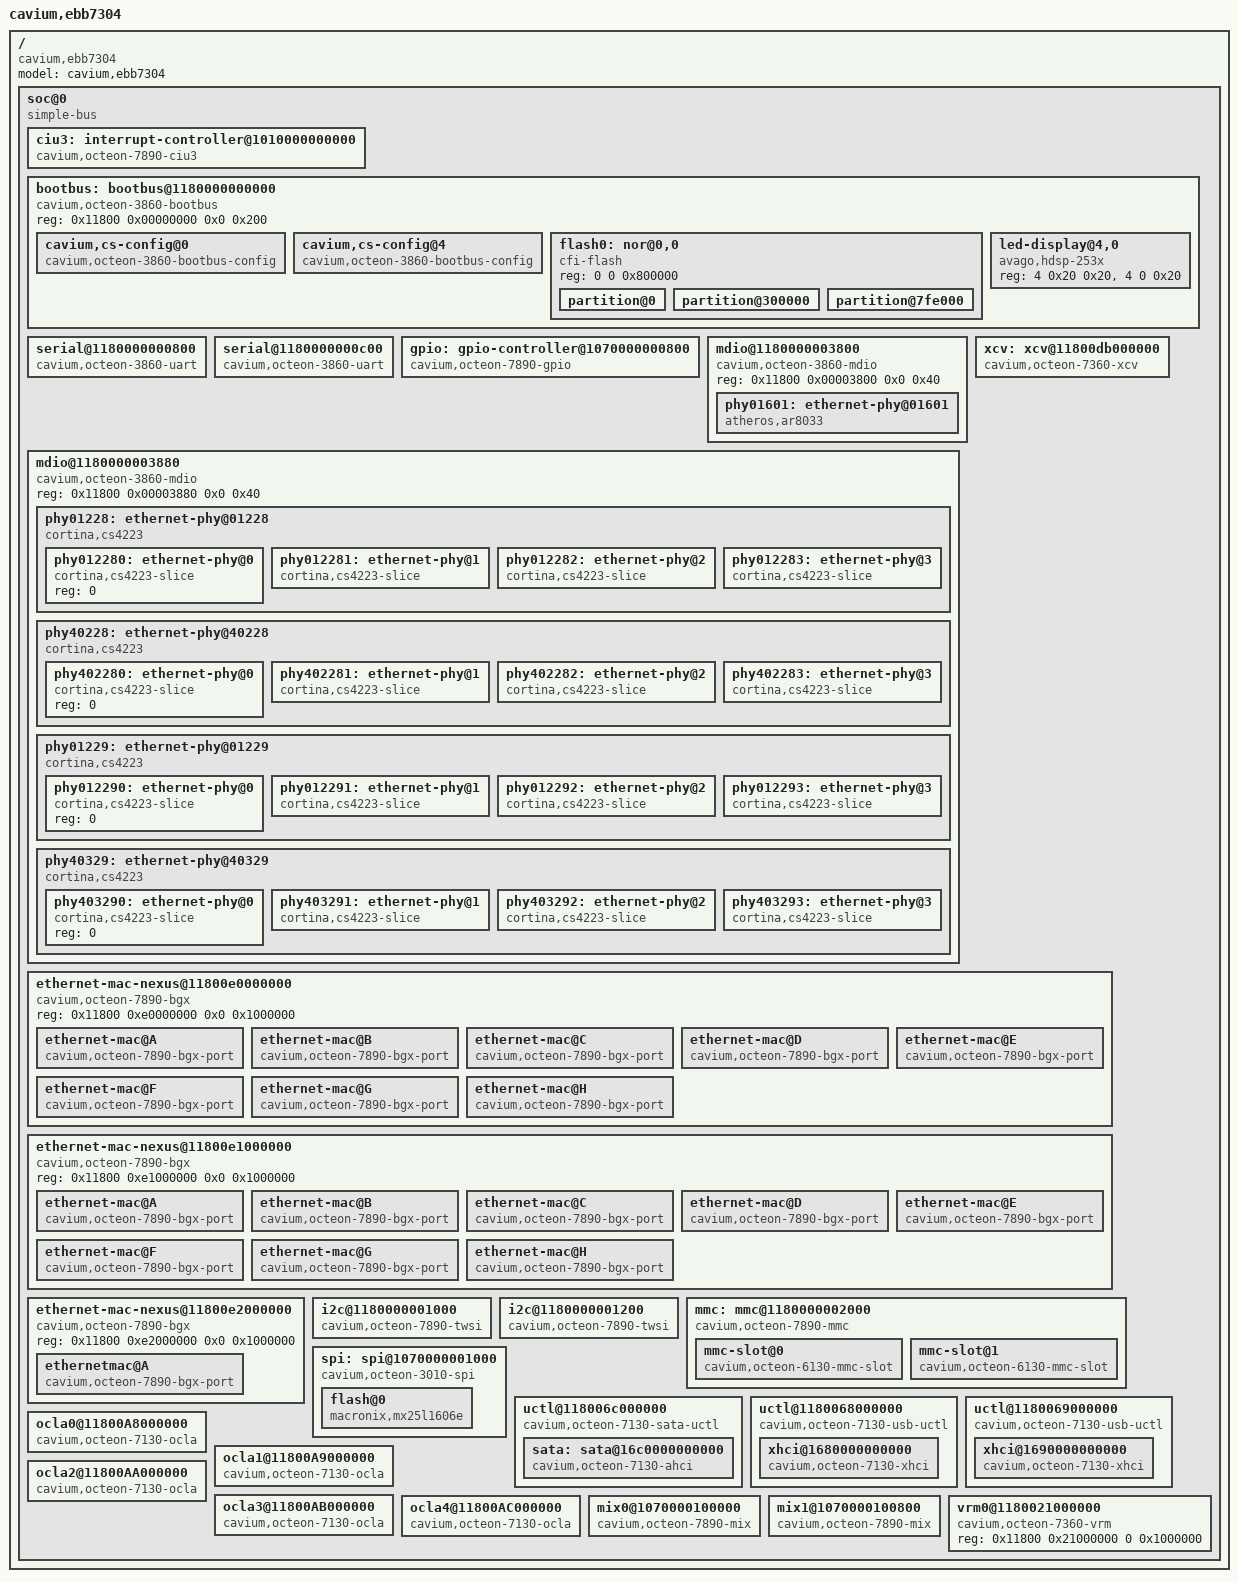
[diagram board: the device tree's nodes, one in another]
/dts-v1/;
/*
 * UBNT E1000
 */
/ {
	model = "cavium,ebb7304";
	compatible = "cavium,ebb7304";
	#address-cells = <2>;
	#size-cells = <2>;

	soc@0 {
		interrupt-parent = <&ciu3>;
		compatible = "simple-bus";
		#address-cells = <2>;
		#size-cells = <2>;
		ranges; /* Direct mapping */
		cavium,node-trim = "0,soc";

		ciu3: interrupt-controller@1010000000000 {
			compatible = "cavium,octeon-7890-ciu3";
			interrupt-controller;
			/* Interrupts are specified by two parts:
			 * 1) Source number (20 significant bits)
			 * 2) Trigger type: (4 == level, 1 == edge)
			 */
			#address-cells = <0>;
			#interrupt-cells = <2>;
			reg = <0x10100 0x00000000 0x0 0xb0000000>;
		};

		bootbus: bootbus@1180000000000 {
			compatible = "cavium,octeon-3860-bootbus";
			reg = <0x11800 0x00000000 0x0 0x200>;
			/* The chip select number and offset */
			#address-cells = <2>;
			/* The size of the chip select region */
			#size-cells = <1>;
			ranges = <0 0  0       0x1f400000  0xc00000>,
				 <1 0  0x10000 0x10000000  0>,
				 <2 0  0x10000 0x20000000  0>,
				 <3 0  0x10000 0x30000000  0>,
				 <4 0  0       0x1d020000  0x10000>,
				 <5 0  0x10000 0x50000000  0>,
				 <6 0  0x10000 0x60000000  0>,
				 <7 0  0x10000 0x70000000  0>;

			cavium,cs-config@0 {
				compatible = "cavium,octeon-3860-bootbus-config";
				cavium,cs-index = <0>;
				cavium,t-adr  = <10>;
				cavium,t-ce   = <50>;
				cavium,t-oe   = <50>;
				cavium,t-we   = <35>;
				cavium,t-rd-hld = <25>;
				cavium,t-wr-hld = <35>;
				cavium,t-pause  = <0>;
				cavium,t-wait   = <50>;
				cavium,t-page   = <30>;
				cavium,t-rd-dly = <0>;

				cavium,page-mode = <1>;
				cavium,pages     = <8>;
				cavium,bus-width = <8>;
			};
			cavium,cs-config@4 {
				compatible = "cavium,octeon-3860-bootbus-config";
				cavium,cs-index = <4>;
				cavium,t-adr  = <10>;
				cavium,t-ce   = <10>;
				cavium,t-oe   = <160>;
				cavium,t-we   = <100>;
				cavium,t-rd-hld = <10>;
				cavium,t-wr-hld = <0>;
				cavium,t-pause  = <50>;
				cavium,t-wait   = <50>;
				cavium,t-page   = <10>;
				cavium,t-rd-dly = <10>;

				cavium,pages     = <0>;
				cavium,bus-width = <8>;
			};
			flash0: nor@0,0 {
				compatible = "cfi-flash";
				reg = <0 0 0x800000>;
				#address-cells = <1>;
				#size-cells = <1>;

				partition@0 {
					label = "bootloader";
					reg = <0 0x340000>;
					read-only;
				};
				partition@300000 {
					label = "storage";
					reg = <0x340000 0x4be000>;
				};
				partition@7fe000 {
					label = "environment";
					reg = <0x7fe000 0x2000>;
					read-only;
				};
			};
			led-display@4,0 {
				compatible = "avago,hdsp-253x";
				reg = <4 0x20 0x20>, <4 0 0x20>;
			};
		};

		serial@1180000000800 {
			compatible = "cavium,octeon-3860-uart","ns16550";
			reg = <0x11800 0x00000800 0x0 0x400>;
			clock-frequency = <0>;
			current-speed = <115200>;
			reg-shift = <3>;
			interrupts = <0x08000 4>;
		};

		serial@1180000000c00 {
			compatible = "cavium,octeon-3860-uart","ns16550";
			reg = <0x11800 0x00000c00 0x0 0x400>;
			clock-frequency = <0>;
			current-speed = <115200>;
			reg-shift = <3>;
			interrupts = <0x08040 4>;
		};

		gpio: gpio-controller@1070000000800 {
			#gpio-cells = <2>;
			compatible = "cavium,octeon-7890-gpio";
			reg = <0x10700 0x00000800 0x0 0x100>;
			gpio-controller;
			/* Interrupts are specified by two parts:
			 * 1) GPIO pin number (0..15)
			 * 2) Triggering (1 - edge rising
			 *		  2 - edge falling
			 *		  4 - level active high
			 *		  8 - level active low)
			 */
			interrupt-controller;
			#interrupt-cells = <2>;
			/* The GPIO pins connect to 16 consecutive CUI bits */
			interrupts = <0x03000 4>, <0x03001 4>,
				     <0x03002 4>, <0x03003 4>,
				     <0x03004 4>, <0x03005 4>,
				     <0x03006 4>, <0x03007 4>,
				     <0x03008 4>, <0x03009 4>,
				     <0x0300a 4>, <0x0300b 4>,
				     <0x0300c 4>, <0x0300d 4>,
				     <0x0300e 4>, <0x0300f 4>;
		};

		mdio@1180000003800 {
			compatible = "cavium,octeon-3860-mdio";
			#address-cells = <1>;
			#size-cells = <0>;
			reg = <0x11800 0x00003800 0x0 0x40>;
			
			phy01601: ethernet-phy@01601 {
				cavium,qlm-trim = "6,sgmii";
				reg = <0x1>;
				compatible = "atheros,ar8033", "ethernet-phy-ieee802.3-c22";
			};
		};
		
		/* SMI_1 -- Available on rev 2 and later boards */
		mdio@1180000003880 {
			compatible = "cavium,octeon-3860-mdio";
			#address-cells = <1>;
			#size-cells = <0>;
			reg = <0x11800 0x00003880 0x0 0x40>;

			/**
			 * The phy names are broken down as follows:
			 * (m)phyxxyzzs
			 * where:
			 *	xx = 01 for SGMII, 10 for DXAUI, 20 for RXAUI
			 *	     and 40 for XFI/LXAUI
			 *	y = QLM/DLM number
			 *	zz = PHY address (decimal)
			 *	s = sub-phy number in the case of the Cortina
			 *	    PHY
			 * a mphy is a nexus phy that contains one or more
			 * sub-phys, for example the Cortina CS4223.
			 */

			/* QLM 2 */
			phy01228: ethernet-phy@01228 {
				compatible = "cortina,cs4223", "ethernet-phy-nexus";
				cavium,qlm-trim = "2,sgmii";						  
				reg = <0x1c>;
				#address-cells = <1>;
				#size-cells = <0>;

				phy012280: ethernet-phy@0 {
					compatible = "cortina,cs4223-slice";
					reg = <0>;					
				};
				phy012281: ethernet-phy@1 {
					compatible = "cortina,cs4223-slice";
					reg = <1>;
					cavium,qlm-trim = "2,sgmii";
				};
				phy012282: ethernet-phy@2 {
					compatible = "cortina,cs4223-slice";
					reg = <2>;
					cavium,qlm-trim = "2,sgmii";
				};
				phy012283: ethernet-phy@3 {
					compatible = "cortina,cs4223-slice";
					reg = <3>;
					cavium,qlm-trim = "2,sgmii";
				};

			};
			
			phy40228: ethernet-phy@40228 {
				compatible = "cortina,cs4223", "ethernet-phy-nexus";
				cavium,qlm-trim = "2,xfi", "2,xlaui", "2,10G_KR",
						  "2,40G_KR4" ;
				reg = <0x1c>;
				#address-cells = <1>;
				#size-cells = <0>;
				/*interrupt-parent = <&gpio>;*/
				/*interrupt = <13 8>;*/
				/* The Cortina CS4223 can be used either as
				 * XFI or XLAUI.  In XFI, four separate ports
				 * are supported even though it's only a single
				 * PHY device.
				 */
				phy402280: ethernet-phy@0 {
					compatible = "cortina,cs4223-slice";
					reg = <0>;					
				};
				phy402281: ethernet-phy@1 {
					compatible = "cortina,cs4223-slice";
					reg = <1>;
					cavium,qlm-trim = "2,xfi","2,10G_KR";
				};
				phy402282: ethernet-phy@2 {
					compatible = "cortina,cs4223-slice";
					reg = <2>;
					cavium,qlm-trim = "2,xfi","2,10G_KR";
				};
				phy402283: ethernet-phy@3 {
					compatible = "cortina,cs4223-slice";
					reg = <3>;
					cavium,qlm-trim = "2,xfi","2,10G_KR";
				};
			};

			/* QLM 3 */
			
			phy01229: ethernet-phy@01229 {
				compatible = "cortina,cs4223", "ethernet-phy-nexus";
				cavium,qlm-trim = "3,sgmii";						  
				reg = <0x1d>;
				#address-cells = <1>;
				#size-cells = <0>;

				phy012290: ethernet-phy@0 {
					compatible = "cortina,cs4223-slice";
					reg = <0>;					
				};
				phy012291: ethernet-phy@1 {
					compatible = "cortina,cs4223-slice";
					reg = <1>;
					cavium,qlm-trim = "3,sgmii";
				};
				phy012292: ethernet-phy@2 {
					compatible = "cortina,cs4223-slice";
					reg = <2>;
					cavium,qlm-trim = "3,sgmii";
				};
				phy012293: ethernet-phy@3 {
					compatible = "cortina,cs4223-slice";
					reg = <3>;
					cavium,qlm-trim = "3,sgmii";
				};

			};
			
			phy40329: ethernet-phy@40329 {
				compatible = "cortina,cs4223", "ethernet-phy-nexus";
				cavium,qlm-trim = "3,xfi","3,xlaui","3,10G_KR",
						  "3,40G_KR4" ;
				#address-cells = <1>;
				#size-cells = <0>;
				reg = <0x1d>;
				interrupt-parent = <&gpio>;
				interrupt = <13 8>;
				/* The Cortina CS4223 can be used either as
				 * XFI or XLAUI.  In XFI, four separate ports
				 * are supported even though it's only a single
				 * PHY device.
				 */
				phy403290: ethernet-phy@0 {
					compatible = "cortina,cs4223-slice";
					reg = <0>;					
				};
				phy403291: ethernet-phy@1 {
					compatible = "cortina,cs4223-slice";
					reg = <1>;
					cavium,qlm-trim = "3,xfi","3,10G_KR";
				};
				phy403292: ethernet-phy@2 {
					compatible = "cortina,cs4223-slice";
					reg = <2>;
					cavium,qlm-trim = "3,xfi","3,10G_KR";
				};
				phy403293: ethernet-phy@3 {
					compatible = "cortina,cs4223-slice";
					reg = <3>;
					cavium,qlm-trim = "3,xfi","3,10G_KR";
				};
			};

			/* DLM 5*/
			
			/* DLM 6 */
			
		};

		xcv: xcv@11800db000000 {
			compatible = "cavium,octeon-7360-xcv";
			reg = <0x11800 0xdb000000 0x0 0x1000000>;
			#address-cells = <1>;
			#size-cells = <0>;
			cavium,xcv-trim = "0,xcv", "1,xcv", "2,xcv";
		};

		/* BGX definitions here must match sim_board.c settings. */
		/* BGX 0*/
		ethernet-mac-nexus@11800e0000000 {
			compatible = "cavium,octeon-7890-bgx";
			reg = <0x11800 0xe0000000 0x0 0x1000000>;
			#address-cells = <1>;
			#size-cells = <0>;

			/* SerDes 0 (XLAUI/XFI) */
			ethernet-mac@A {
				compatible = "cavium,octeon-7890-bgx-port";
				reg = <0>;
				local-mac-address = [ 00 00 00 00 00 00 ];
				phy-handle = <&phy402280>;
				cavium,qlm-trim = "2,xlaui", "2,xfi","2,10G_KR","2,40G_KR4";	
				
				
			};
			
			/* SerDes 1 (XFI) */
			ethernet-mac@B {
				compatible = "cavium,octeon-7890-bgx-port";
				reg = <1>;
				local-mac-address = [ 00 00 00 00 00 00 ];
				phy-handle = <&phy402281>;
				cavium,qlm-trim = "2,xfi","2,10G_KR";
				
			};
			
			/* SerDes 2 (XFI) */
			ethernet-mac@C {
				compatible = "cavium,octeon-7890-bgx-port";
				reg = <2>;
				local-mac-address = [ 00 00 00 00 00 00 ];
				phy-handle = <&phy402282>;
				cavium,qlm-trim = "2,xfi","2,10G_KR";
				
			};
			/* SerDes 3 (XFI) */
			ethernet-mac@D {
				compatible = "cavium,octeon-7890-bgx-port";
				reg = <3>;
				local-mac-address = [ 00 00 00 00 00 00 ];
				phy-handle = <&phy402283>;
				cavium,qlm-trim = "2,xfi","2,10G_KR";
				
			};

			/* SerDes 0 (SGMII) */
			ethernet-mac@E {
				compatible = "cavium,octeon-7890-bgx-port";
				reg = <0>;
				local-mac-address = [ 00 00 00 00 00 00 ];
				phy-handle = <&phy012280>;
				cavium,qlm-trim = "2,sgmii";	
			};

			ethernet-mac@F {
				compatible = "cavium,octeon-7890-bgx-port";
				reg = <1>;
				local-mac-address = [ 00 00 00 00 00 00 ];
				phy-handle = <&phy012281>;
				cavium,qlm-trim = "2,sgmii";	
			};

			ethernet-mac@G {
				compatible = "cavium,octeon-7890-bgx-port";
				reg = <2>;
				local-mac-address = [ 00 00 00 00 00 00 ];
				phy-handle = <&phy012282>;
				cavium,qlm-trim = "2,sgmii";	
			};

			ethernet-mac@H {
				compatible = "cavium,octeon-7890-bgx-port";
				reg = <3>;
				local-mac-address = [ 00 00 00 00 00 00 ];
				phy-handle = <&phy012283>;
				cavium,qlm-trim = "2,sgmii";	
			};
			
		};
		/* BGX 1*/
		ethernet-mac-nexus@11800e1000000 {
			compatible = "cavium,octeon-7890-bgx";
			reg = <0x11800 0xe1000000 0x0 0x1000000>;
			#address-cells = <1>;
			#size-cells = <0>;

			
			/* SerDes 0 (XLAUI/XFI) */
			ethernet-mac@A {
				compatible = "cavium,octeon-7890-bgx-port";
				reg = <0>;
				local-mac-address = [ 00 00 00 00 00 00 ];
				phy-handle = <&phy403290>;
				cavium,qlm-trim = "3,xlaui","3,xfi","3,10G_KR","3,40G_KR4";				
				
			};
			
			/* SerDes 1 (XFI) */
			ethernet-mac@B {
				compatible = "cavium,octeon-7890-bgx-port";
				reg = <1>;
				local-mac-address = [ 00 00 00 00 00 00 ];
				phy-handle = <&phy403291>;
				cavium,qlm-trim = "3,xfi","3,10G_KR";
				
			};
			/* SerDes 2 (XFI) */
			ethernet-mac@C {
				compatible = "cavium,octeon-7890-bgx-port";
				reg = <2>;
				local-mac-address = [ 00 00 00 00 00 00 ];
				phy-handle = <&phy403292>;
				cavium,qlm-trim = "3,xfi","3,10G_KR";
				
			};

			/* SerDes 3 (XFI) */
			ethernet-mac@D {
				compatible = "cavium,octeon-7890-bgx-port";
				reg = <3>;
				local-mac-address = [ 00 00 00 00 00 00 ];
				phy-handle = <&phy403293>;
				cavium,qlm-trim = "3,xfi","3,10G_KR";
				
			};

			/* SerDes 0 (SGMII) */
			ethernet-mac@E {
				compatible = "cavium,octeon-7890-bgx-port";
				reg = <0>;
				local-mac-address = [ 00 00 00 00 00 00 ];
				phy-handle = <&phy012290>;
				cavium,qlm-trim = "3,sgmii";	
			};

			ethernet-mac@F {
				compatible = "cavium,octeon-7890-bgx-port";
				reg = <1>;
				local-mac-address = [ 00 00 00 00 00 00 ];
				phy-handle = <&phy012291>;
				cavium,qlm-trim = "3,sgmii";	
			};

			ethernet-mac@G {
				compatible = "cavium,octeon-7890-bgx-port";
				reg = <2>;
				local-mac-address = [ 00 00 00 00 00 00 ];
				phy-handle = <&phy012292>;
				cavium,qlm-trim = "3,sgmii";	
			};

			ethernet-mac@H {
				compatible = "cavium,octeon-7890-bgx-port";
				reg = <3>;
				local-mac-address = [ 00 00 00 00 00 00 ];
				phy-handle = <&phy012293>;
				cavium,qlm-trim = "3,sgmii";	
			};
		
		};

		/* BGX 2 */
		ethernet-mac-nexus@11800e2000000 {
			compatible = "cavium,octeon-7890-bgx";
			reg = <0x11800 0xe2000000 0x0 0x1000000>;
			#address-cells = <1>;
			#size-cells = <0>;
			
			/* SerDes 0, may differ from PCS Lane/LMAC */
			ethernetmac@A {
				compatible = "cavium,octeon-7890-bgx-port";
				reg = <2>;
				local-mac-address = [ 00 00 00 00 00 00 ];
				phy-handle = <&phy01601>;
				cavium,qlm-trim = "6,sgmii";				
			};
		};

		i2c@1180000001000 {
			#address-cells = <1>;
			#size-cells = <0>;
			compatible = "cavium,octeon-7890-twsi";
			cavium,cpu-trim = "0,notrev1.0";
			reg = <0x11800 0x00001000 0x0 0x200>;
			/* INT_ST, INT_TS, INT_CORE */
			interrupts = <0x0b000 1>, <0x0b001 1>, <0x0b002 1>;
			clock-frequency = <100000>;
		};

		i2c@1180000001200 {
			#address-cells = <1>;
			#size-cells = <0>;
			compatible = "cavium,octeon-7890-twsi";
			reg = <0x11800 0x00001200 0x0 0x200>;
			/* INT_ST, INT_TS, INT_CORE */
			interrupts = <0x0b100 1>, <0x0b101 1>, <0x0b102 1>;
			clock-frequency = <100000>;
		};

		mmc: mmc@1180000002000 {
			compatible = "cavium,octeon-7890-mmc",
				     "cavium,octeon-7360-mmc";
			reg = <0x11800 0x00002000 0x0 0x100>,
			      <0x11800 0x00000180 0x0 0x20>;
			#address-cells = <1>;
			#size-cells = <0>;
			/* EMM_INT_BUF_DONE,
			   EMM_INT_CMD_DONE,
			   EMM_INT_DMA_DONE,
			   EMM_INT_CMD_ERR,
			   EMM_INT_DMA_ERR,
			   EMM_INT_SWITCH_DONE,
			   EMM_INT_SWITCH_ERR,
			   EMM_DMA_DONE,
			   EMM_DMA_FIFO*/
			interrupts = <0x09040 1>,
				     <0x09041 1>,
				     <0x09042 1>,
				     <0x09043 1>,
				     <0x09044 1>,
				     <0x09045 1>,
				     <0x09046 1>,
				     <0x09000 1>,
				     <0x09001 1>;

			/* Power on GPIO 8, active high */
			power-gpios = <&gpio 8 0>;

			/* The board has two MMC slots
			 * If both are occupied, the speed must be reduced,
			 * as extra data-line load increases slew time,
			 * and dat-skew adjustment does not help significantly.
			 */
			mmc-slot@0 {
				compatible = "cavium,octeon-6130-mmc-slot";
				reg = <0>;
				voltage-ranges = <3300 3300>;
				//spi-max-frequency = <52000000>; // just one
				spi-max-frequency = <26000000>; // both slots
				/* bus width can be 1, 4 or 8 */
				bus-width = <8>; /* new std property */
				cavium,bus-max-width = <8>; /* custom property */
				
			};

			mmc-slot@1 {
				compatible = "cavium,octeon-6130-mmc-slot";
				reg = <1>;
				voltage-ranges = <3300 3300>;
				//spi-max-frequency = <52000000>; // just one
				spi-max-frequency = <26000000>; // both slots
				/* bus width can be 1, 4 or 8 */
				bus-width = <8>; /* new std property */
				cavium,bus-max-width = <8>; /* custom property */
				
			};
		};

		spi: spi@1070000001000 {
			compatible = "cavium,octeon-3010-spi";
			reg = <0x10700 0x00001000 0x0 0x100>;
			interrupts = <0x05001 1>;
			#address-cells = <1>;
			#size-cells = <0>;
			spi-max-frequency = <25000000>;

			flash@0 {
				compatible = "macronix,mx25l1606e","spi-flash";
				reg = <0>;
				spi-max-frequency = <75000000>;

				pagesize = <0x10000>;
				size = <0x1000000>;
				address-width = <32>;
			};
		};

		uctl@118006c000000 {
			compatible = "cavium,octeon-7130-sata-uctl";
			reg = <0x11800 0x6c000000 0x0 0x100>;
			ranges; /* Direct mapping */
			#address-cells = <2>;
			#size-cells = <2>;
			portmap = <0x3>;
			staggered-spinup;
			cavium,qlm-trim = "4,sata";

			sata: sata@16c0000000000 {
				compatible = "cavium,octeon-7130-ahci";
				reg = <0x16c00 0x00000000 0x0 0x200>;
				#address-cells = <2>;
				#size-cells = <2>;
				interrupts = <0x6c010 4>;
			};
		};

		/* USB 0 */
		uctl@1180068000000 {
			compatible = "cavium,octeon-7130-usb-uctl";
			reg = <0x11800 0x68000000 0x0 0x100>;
			ranges; /* Direct mapping */
			#address-cells = <2>;
			#size-cells = <2>;
			/* Only 100MHz allowed */
			refclk-frequency = <100000000>;
			/* Only "dlmc_ref_clk0" is supported for 73xx */
			refclk-type-ss = "dlmc_ref_clk0";
			/* Only "dlmc_ref_clk0" is supported for 73xx */
			refclk-type-hs = "dlmc_ref_clk0";

			/* Power is specified by three parts:
			 * 1) GPIO handle (must be &gpio)
			 * 2) GPIO pin number
			 * 3) Active high (0) or active low (1)
			 */
			power = <&gpio 20 0>;

			xhci@1680000000000 {
				compatible = "cavium,octeon-7130-xhci","synopsys,dwc3";
				reg = <0x16800 0x00000000 0x10 0x0>;
				interrupts = <0x68080 4>; /* UAHC_IMAN, level */
			};
		};

		/* USB 1 */
		uctl@1180069000000 {
			compatible = "cavium,octeon-7130-usb-uctl";
			reg = <0x11800 0x69000000 0x0 0x100>;
			ranges; /* Direct mapping */
			#address-cells = <2>;
			#size-cells = <2>;
			/* 50MHz, 100MHz and 125MHz allowed */
			refclk-frequency = <100000000>;
			/* Either "dlmc_ref_clk0" or "dlmc_ref_clk0" */
			refclk-type-ss = "dlmc_ref_clk0";
			/* Either "dlmc_ref_clk0" "dlmc_ref_clk1" or "pll_ref_clk" */
			refclk-type-hs = "dlmc_ref_clk0";

			/* Power is specified by three parts:
			 * 1) GPIO handle (must be &gpio)
			 * 2) GPIO pin number
			 * 3) Active high (0) or active low (1)
			 */
			power = <&gpio 21 0>;

			xhci@1690000000000 {
				compatible = "cavium,octeon-7130-xhci","synopsys,dwc3";
				reg = <0x16900 0x00000000 0x10 0x0>;
				interrupts = <0x69080 4>; /* UAHC_IMAN, level */
			};
		};

		ocla0@11800A8000000 {
			compatible = "cavium,octeon-7130-ocla";
			reg = <0x11800 0xa8000000 0x0 0x500000>;
			interrupts = <0xa800c 1>, /* Fsm0 */
				     <0xa800d 1>, /* Fsm1 */
				     <0xa800f 1>; /* Trigfull */
		};

		ocla1@11800A9000000 {
			compatible = "cavium,octeon-7130-ocla";
			reg = <0x11800 0xa9000000 0x0 0x500000>;
			interrupts = <0xa900c 1>, /* Fsm0 */
				     <0xa900d 1>, /* Fsm1 */
				     <0xa900f 1>; /* Trigfull */
		};

		ocla2@11800AA000000 {
			compatible = "cavium,octeon-7130-ocla";
			reg = <0x11800 0xaa000000 0x0 0x500000>;
			interrupts = <0xaa00c 1>, /* Fsm0 */
				     <0xaa00d 1>, /* Fsm1 */
				     <0xaa00f 1>; /* Trigfull */
		};

		ocla3@11800AB000000 {
			compatible = "cavium,octeon-7130-ocla";
			reg = <0x11800 0xab000000 0x0 0x500000>;
			interrupts = <0xab00c 1>, /* Fsm0 */
				     <0xab00d 1>, /* Fsm1 */
				     <0xab00f 1>; /* Trigfull */
		};

		ocla4@11800AC000000 {
			compatible = "cavium,octeon-7130-ocla";
			reg = <0x11800 0xac000000 0x0 0x500000>;
			interrupts = <0xac00c 1>, /* Fsm0 */
				     <0xac00d 1>, /* Fsm1 */
				     <0xac00f 1>; /* Trigfull */
		};

		mix0@1070000100000 {
			compatible = "cavium,octeon-7890-mix";
			reg = <0x10700 0x00100000 0x0 0x100>;
			interrupts = <0x10000 1>, /* ODBLOVF */
				     <0x10001 1>, /* IDBLOVF */
				     <0x10002 1>, /* ORTHRESH */
				     <0x10003 1>, /* IRTHRESH */
				     <0x10004 1>, /* DATA_DRP */
				     <0x10005 1>, /* IRUN */
				     <0x10006 1>, /* ORUN */
				     <0x10007 1>; /* TS */
			local-mac-address = [ 00 00 00 00 00 00 ];
			cavium,mac-handle = <0xffff>;
		};
		mix1@1070000100800 {
			compatible = "cavium,octeon-7890-mix";
			reg = <0x10700 0x00100800 0x0 0x100>;
			interrupts = <0x10010 1>, /* ODBLOVF */
				     <0x10011 1>, /* IDBLOVF */
				     <0x10012 1>, /* ORTHRESH */
				     <0x10013 1>, /* IRTHRESH */
				     <0x10014 1>, /* DATA_DRP */
				     <0x10015 1>, /* IRUN */
				     <0x10016 1>, /* ORUN */
				     <0x10017 1>; /* TS */
			local-mac-address = [ 00 00 00 00 00 00 ];
			cavium,mac-handle = <0xffff>;
		};

		vrm0@1180021000000 {
			compatible = "cavium,octeon-7360-vrm";
			reg = <0x11800 0x21000000 0 0x1000000>;
		};
	};
 };

